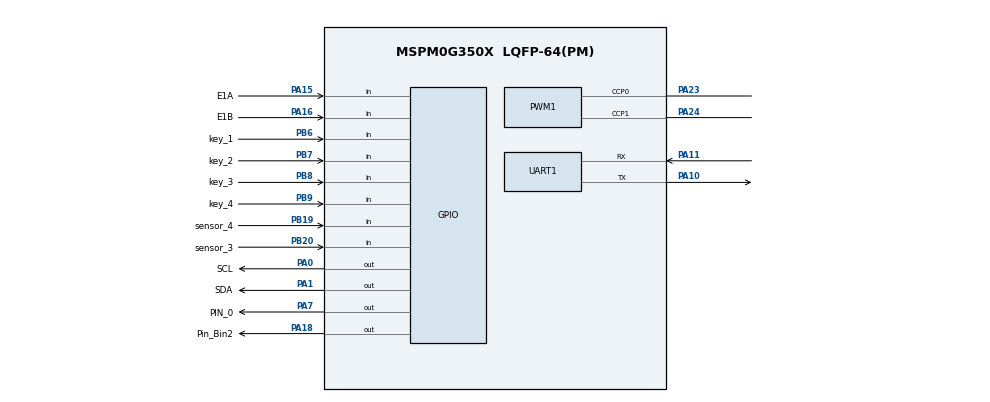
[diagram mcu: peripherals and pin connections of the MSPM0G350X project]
/**
 * @cliArgs --device "MSPM0G350X" --package "LQFP-64(PM)" --part "Default" --product "mspm0_sdk@2.01.00.03"
 * @versions {"tool":"1.20.0+3587"}
 */

/**
 * Import the modules used in this configuration.
 */
const GPIO    = scripting.addModule("/ti/driverlib/GPIO", {}, false);
const GPIO1   = GPIO.addInstance();
const GPIO2   = GPIO.addInstance();
const GPIO3   = GPIO.addInstance();
const GPIO4   = GPIO.addInstance();
const GPIO5   = GPIO.addInstance();
const GPIO6   = GPIO.addInstance();
const GPIO7   = GPIO.addInstance();
const GPIO8   = GPIO.addInstance();
const GPIO9   = GPIO.addInstance();
const GPIO10  = GPIO.addInstance();
const GPIO11  = GPIO.addInstance();
const PWM     = scripting.addModule("/ti/driverlib/PWM", {}, false);
const PWM1    = PWM.addInstance();
const SYSCTL  = scripting.addModule("/ti/driverlib/SYSCTL");
const SYSTICK = scripting.addModule("/ti/driverlib/SYSTICK");
const TIMER   = scripting.addModule("/ti/driverlib/TIMER", {}, false);
const TIMER1  = TIMER.addInstance();
const UART    = scripting.addModule("/ti/driverlib/UART", {}, false);
const UART1   = UART.addInstance();

/**
 * Write custom configuration values to the imported modules.
 */
GPIO1.$name                              = "LED1";
GPIO1.port                               = "PORTA";
GPIO1.associatedPins[0].$name            = "PIN_0";
GPIO1.associatedPins[0].internalResistor = "PULL_DOWN";
GPIO1.associatedPins[0].assignedPin      = "7";
GPIO1.associatedPins[0].pin.$assign      = "PA7";

const Board = scripting.addModule("/ti/driverlib/Board", {}, false);

GPIO2.$name                               = "ENCODERA";
GPIO2.port                                = "PORTA";
GPIO2.associatedPins.create(2);
GPIO2.associatedPins[0].direction         = "INPUT";
GPIO2.associatedPins[0].interruptEn       = true;
GPIO2.associatedPins[0].polarity          = "RISE";
GPIO2.associatedPins[0].interruptPriority = "0";
GPIO2.associatedPins[0].$name             = "E1A";
GPIO2.associatedPins[0].assignedPin       = "15";
GPIO2.associatedPins[0].pin.$assign       = "PA15";
GPIO2.associatedPins[1].direction         = "INPUT";
GPIO2.associatedPins[1].interruptEn       = true;
GPIO2.associatedPins[1].polarity          = "RISE";
GPIO2.associatedPins[1].interruptPriority = "0";
GPIO2.associatedPins[1].$name             = "E1B";
GPIO2.associatedPins[1].assignedPin       = "16";
GPIO2.associatedPins[1].pin.$assign       = "PA16";

GPIO3.$name                         = "AIN1";
GPIO3.port                          = "PORTA";
GPIO3.associatedPins[0].$name       = "PIN_12";
GPIO3.associatedPins[0].assignedPin = "12";

GPIO4.$name                         = "AIN2";
GPIO4.port                          = "PORTA";
GPIO4.associatedPins[0].$name       = "PIN_13";
GPIO4.associatedPins[0].assignedPin = "13";

GPIO5.$name                                       = "BIN1";
GPIO5.port                                        = "PORTA";
GPIO5.associatedPins[0].$name                     = "Pin_Bin1";
GPIO5.associatedPins[0].assignedPin               = "14";
GPIO5.associatedPins[0].pin.$assignAllowConflicts = "PA14";

GPIO6.$name                         = "BIN2";
GPIO6.port                          = "PORTA";
GPIO6.associatedPins[0].$name       = "Pin_Bin2";
GPIO6.associatedPins[0].assignedPin = "18";
GPIO6.associatedPins[0].pin.$assign = "PA18";

GPIO7.$name                               = "ENCODERB";
GPIO7.port                                = "PORTA";
GPIO7.associatedPins.create(2);
GPIO7.associatedPins[0].$name             = "E2A";
GPIO7.associatedPins[0].direction         = "INPUT";
GPIO7.associatedPins[0].assignedPin       = "17";
GPIO7.associatedPins[0].interruptEn       = true;
GPIO7.associatedPins[0].polarity          = "RISE";
GPIO7.associatedPins[0].interruptPriority = "0";
GPIO7.associatedPins[1].$name             = "E2B";
GPIO7.associatedPins[1].direction         = "INPUT";
GPIO7.associatedPins[1].assignedPin       = "22";
GPIO7.associatedPins[1].interruptEn       = true;
GPIO7.associatedPins[1].polarity          = "RISE";
GPIO7.associatedPins[1].interruptPriority = "0";

GPIO8.$name                         = "BUZZER";
GPIO8.port                          = "PORTA";
GPIO8.associatedPins[0].assignedPin = "8";
GPIO8.associatedPins[0].$name       = "BUZZER_PIN_8";

GPIO9.$name                         = "OLED";
GPIO9.port                          = "PORTA";
GPIO9.associatedPins.create(2);
GPIO9.associatedPins[0].$name       = "SCL";
GPIO9.associatedPins[0].ioStructure = "OD";
GPIO9.associatedPins[0].assignedPin = "0";
GPIO9.associatedPins[0].pin.$assign = "PA0";
GPIO9.associatedPins[1].$name       = "SDA";
GPIO9.associatedPins[1].ioStructure = "OD";
GPIO9.associatedPins[1].assignedPin = "1";
GPIO9.associatedPins[1].pin.$assign = "PA1";

GPIO10.$name                               = "infrared_tube_pair";
GPIO10.associatedPins.create(4);
GPIO10.associatedPins[0].assignedPort      = "PORTA";
GPIO10.associatedPins[0].direction         = "INPUT";
GPIO10.associatedPins[0].$name             = "sensor_1";
GPIO10.associatedPins[0].assignedPin       = "2";
GPIO10.associatedPins[0].interruptEn       = true;
GPIO10.associatedPins[0].polarity          = "RISE_FALL";
GPIO10.associatedPins[0].interruptPriority = "2";
GPIO10.associatedPins[1].direction         = "INPUT";
GPIO10.associatedPins[1].$name             = "sensor_2";
GPIO10.associatedPins[1].interruptEn       = true;
GPIO10.associatedPins[1].assignedPort      = "PORTB";
GPIO10.associatedPins[1].assignedPin       = "24";
GPIO10.associatedPins[1].polarity          = "RISE_FALL";
GPIO10.associatedPins[1].interruptPriority = "2";
GPIO10.associatedPins[2].direction         = "INPUT";
GPIO10.associatedPins[2].$name             = "sensor_3";
GPIO10.associatedPins[2].assignedPort      = "PORTB";
GPIO10.associatedPins[2].assignedPin       = "20";
GPIO10.associatedPins[2].interruptEn       = true;
GPIO10.associatedPins[2].polarity          = "RISE_FALL";
GPIO10.associatedPins[2].interruptPriority = "2";
GPIO10.associatedPins[2].pin.$assign       = "PB20";
GPIO10.associatedPins[3].direction         = "INPUT";
GPIO10.associatedPins[3].$name             = "sensor_4";
GPIO10.associatedPins[3].assignedPort      = "PORTB";
GPIO10.associatedPins[3].assignedPin       = "19";
GPIO10.associatedPins[3].interruptEn       = true;
GPIO10.associatedPins[3].polarity          = "RISE_FALL";
GPIO10.associatedPins[3].interruptPriority = "2";
GPIO10.associatedPins[3].pin.$assign       = "PB19";

GPIO11.$name                               = "KEYs";
GPIO11.port                                = "PORTB";
GPIO11.associatedPins.create(4);
GPIO11.associatedPins[0].$name             = "key_1";
GPIO11.associatedPins[0].direction         = "INPUT";
GPIO11.associatedPins[0].polarity          = "RISE_FALL";
GPIO11.associatedPins[0].interruptEn       = true;
GPIO11.associatedPins[0].interruptPriority = "3";
GPIO11.associatedPins[0].assignedPin       = "6";
GPIO11.associatedPins[0].pin.$assign       = "PB6";
GPIO11.associatedPins[1].$name             = "key_2";
GPIO11.associatedPins[1].direction         = "INPUT";
GPIO11.associatedPins[1].interruptEn       = true;
GPIO11.associatedPins[1].polarity          = "RISE_FALL";
GPIO11.associatedPins[1].interruptPriority = "3";
GPIO11.associatedPins[1].assignedPin       = "7";
GPIO11.associatedPins[1].pin.$assign       = "PB7";
GPIO11.associatedPins[2].$name             = "key_3";
GPIO11.associatedPins[2].direction         = "INPUT";
GPIO11.associatedPins[2].polarity          = "RISE_FALL";
GPIO11.associatedPins[2].interruptEn       = true;
GPIO11.associatedPins[2].interruptPriority = "3";
GPIO11.associatedPins[2].assignedPin       = "8";
GPIO11.associatedPins[2].pin.$assign       = "PB8";
GPIO11.associatedPins[3].$name             = "key_4";
GPIO11.associatedPins[3].direction         = "INPUT";
GPIO11.associatedPins[3].polarity          = "RISE_FALL";
GPIO11.associatedPins[3].interruptEn       = true;
GPIO11.associatedPins[3].interruptPriority = "3";
GPIO11.associatedPins[3].assignedPin       = "9";
GPIO11.associatedPins[3].pin.$assign       = "PB9";

PWM1.$name                      = "PWM_0";
PWM1.clockDivider               = 8;
PWM1.timerCount                 = 10000;
PWM1.timerStartTimer            = true;
PWM1.peripheral.$assign         = "TIMG7";
PWM1.peripheral.ccp0Pin.$assign = "PA23";
PWM1.peripheral.ccp1Pin.$assign = "PA24";
PWM1.PWM_CHANNEL_0.$name        = "ti_driverlib_pwm_PWMTimerCC0";
PWM1.PWM_CHANNEL_1.$name        = "ti_driverlib_pwm_PWMTimerCC1";
PWM1.ccp0PinConfig.$name        = "ti_driverlib_gpio_GPIOPinGeneric2";
PWM1.ccp1PinConfig.$name        = "ti_driverlib_gpio_GPIOPinGeneric3";

SYSCTL.forceDefaultClkConfig = true;
SYSCTL.clockTreeEn           = true;

SYSTICK.periodEnable      = true;
SYSTICK.systickEnable     = true;
SYSTICK.interruptPriority = "0";
SYSTICK.period            = 32;

TIMER1.$name             = "TIMER_0";
TIMER1.timerClkDiv       = 8;
TIMER1.timerClkPrescale  = 200;
TIMER1.timerPeriod       = "5 ms";
TIMER1.timerStartTimer   = true;
TIMER1.timerMode         = "PERIODIC";
TIMER1.interrupts        = ["ZERO"];
TIMER1.interruptPriority = "3";

UART1.$name                    = "UART_0";
UART1.enabledInterrupts        = ["RX"];
UART1.interruptPriority        = "1";
UART1.targetBaudRate           = 115200;
UART1.peripheral.$assign       = "UART0";
UART1.peripheral.rxPin.$assign = "PA11";
UART1.peripheral.txPin.$assign = "PA10";
UART1.txPinConfig.$name        = "ti_driverlib_gpio_GPIOPinGeneric0";
UART1.rxPinConfig.$name        = "ti_driverlib_gpio_GPIOPinGeneric1";

/**
 * Pinmux solution for unlocked pins/peripherals. This ensures that minor changes to the automatic solver in a future
 * version of the tool will not impact the pinmux you originally saw.  These lines can be completely deleted in order to
 * re-solve from scratch.
 */
Board.peripheral.$suggestSolution             = "DEBUGSS";
Board.peripheral.swclkPin.$suggestSolution    = "PA20";
Board.peripheral.swdioPin.$suggestSolution    = "PA19";
GPIO3.associatedPins[0].pin.$suggestSolution  = "PA12";
GPIO4.associatedPins[0].pin.$suggestSolution  = "PA13";
GPIO7.associatedPins[0].pin.$suggestSolution  = "PA17";
GPIO7.associatedPins[1].pin.$suggestSolution  = "PA22";
GPIO8.associatedPins[0].pin.$suggestSolution  = "PA8";
GPIO10.associatedPins[0].pin.$suggestSolution = "PA2";
GPIO10.associatedPins[1].pin.$suggestSolution = "PB24";
TIMER1.peripheral.$suggestSolution            = "TIMA0";
